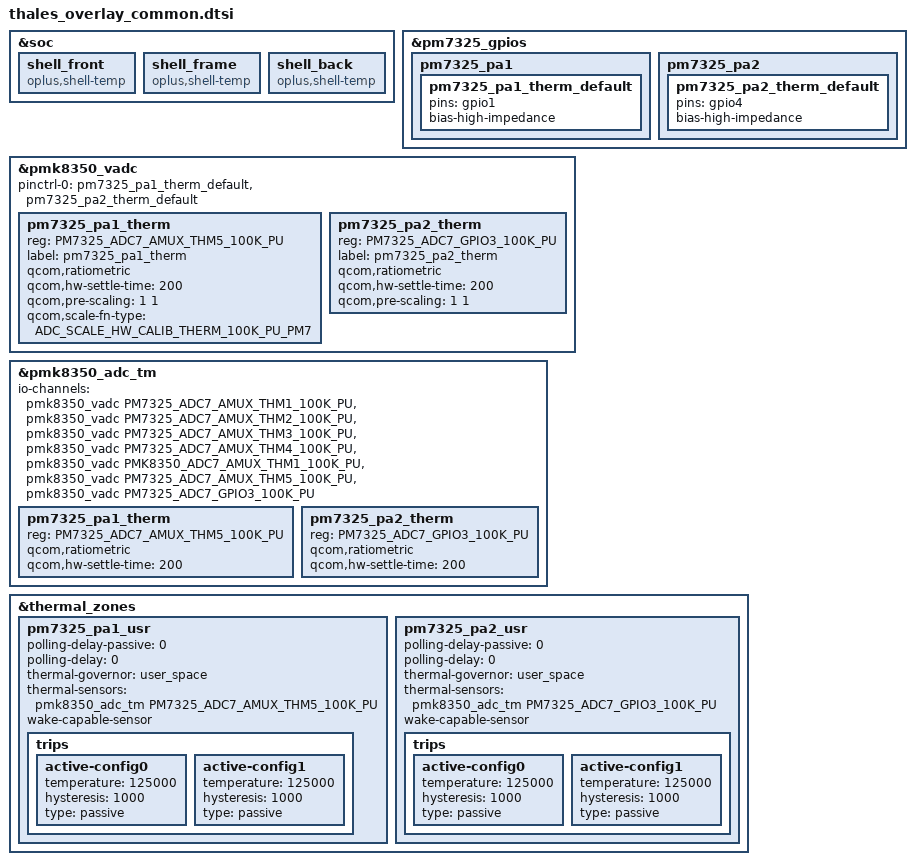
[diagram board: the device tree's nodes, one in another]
/*#ifdef OPLUS_FEATURE_THERMAL*/
#include <dt-bindings/iio/qcom,spmi-vadc.h>
&soc {
	//#ifdef OPLUS_FEATURE_THERMAL_HORAE
	shell_front {
			compatible = "oplus,shell-temp";
	};

	shell_frame {
			compatible = "oplus,shell-temp";
	};

	shell_back {
			compatible = "oplus,shell-temp";
	};
	//#endif

};

&pm7325_gpios {
	pm7325_pa1 {
		pm7325_pa1_therm_default: pm7325_pa1_therm_default {
			pins = "gpio1";
			bias-high-impedance;
		};
	};
	pm7325_pa2 {
                pm7325_pa2_therm_default: pm7325_pa2_therm_default {
                        pins = "gpio4";
                        bias-high-impedance;
                };
        };
};

&pmk8350_vadc {
    pinctrl-names = "default";
	pinctrl-0 = <&pm7325_pa1_therm_default &pm7325_pa2_therm_default>;
	pm7325_pa1_therm {
		reg = <PM7325_ADC7_AMUX_THM5_100K_PU>;
                label = "pm7325_pa1_therm";
                qcom,ratiometric;
                qcom,hw-settle-time = <200>;
                qcom,pre-scaling = <1 1>;
		qcom,scale-fn-type = <ADC_SCALE_HW_CALIB_THERM_100K_PU_PM7>;
	};

	pm7325_pa2_therm {
                reg = <PM7325_ADC7_GPIO3_100K_PU>;
                label = "pm7325_pa2_therm";
                qcom,ratiometric;
                qcom,hw-settle-time = <200>;
                qcom,pre-scaling = <1 1>;
        };
};

&pmk8350_adc_tm {
        io-channels = <&pmk8350_vadc PM7325_ADC7_AMUX_THM1_100K_PU>,
                        <&pmk8350_vadc PM7325_ADC7_AMUX_THM2_100K_PU>,
                        <&pmk8350_vadc PM7325_ADC7_AMUX_THM3_100K_PU>,
                        <&pmk8350_vadc PM7325_ADC7_AMUX_THM4_100K_PU>,
                        <&pmk8350_vadc PMK8350_ADC7_AMUX_THM1_100K_PU>,
                        <&pmk8350_vadc PM7325_ADC7_AMUX_THM5_100K_PU>,
                        <&pmk8350_vadc PM7325_ADC7_GPIO3_100K_PU>;

	pm7325_pa1_therm {
                reg = <PM7325_ADC7_AMUX_THM5_100K_PU>;
                qcom,ratiometric;
                qcom,hw-settle-time = <200>;
        };

	pm7325_pa2_therm {
                reg = <PM7325_ADC7_GPIO3_100K_PU>;
                qcom,ratiometric;
                qcom,hw-settle-time = <200>;
        };
};

&thermal_zones {
	pm7325_pa1_usr {
                polling-delay-passive = <0>;
                polling-delay = <0>;
                thermal-governor = "user_space";
                thermal-sensors = <&pmk8350_adc_tm PM7325_ADC7_AMUX_THM5_100K_PU>;
                wake-capable-sensor;
                trips {
                        active-config0 {
                                temperature = <125000>;
                                hysteresis = <1000>;
                                type = "passive";
                        };

                        active-config1 {
                                temperature = <125000>;
                                hysteresis = <1000>;
                                type = "passive";
                        };
                };
        };

	pm7325_pa2_usr {
                polling-delay-passive = <0>;
                polling-delay = <0>;
                thermal-governor = "user_space";
                thermal-sensors = <&pmk8350_adc_tm PM7325_ADC7_GPIO3_100K_PU>;
                wake-capable-sensor;
                trips {
                        active-config0 {
                                temperature = <125000>;
                                hysteresis = <1000>;
                                type = "passive";
                        };

                        active-config1 {
                                temperature = <125000>;
                                hysteresis = <1000>;
                                type = "passive";
                        };
                };
        };
};
//#endif OPLUS_FEATURE_THERMAL
